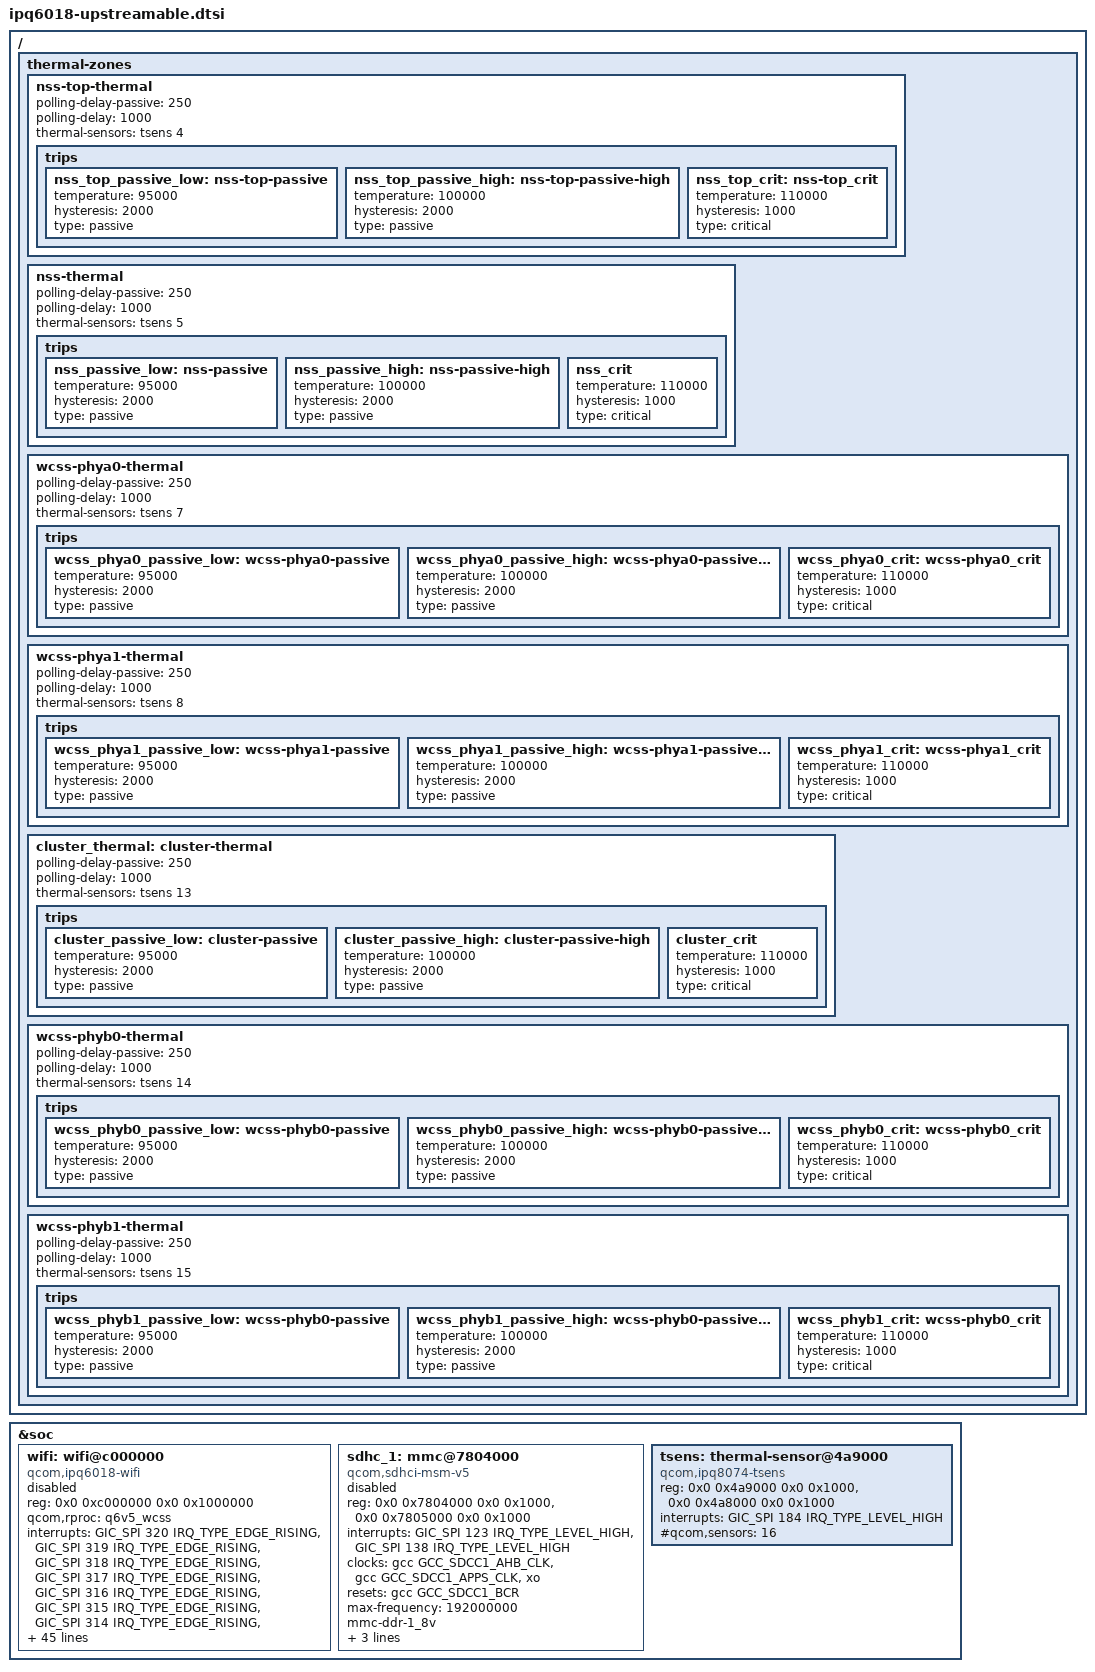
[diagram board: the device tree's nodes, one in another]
/*
 * Copyright (c) 2019-2020, The Linux Foundation. All rights reserved.
 *
 * Permission to use, copy, modify, and/or distribute this software for any
 * purpose with or without fee is hereby granted, provided that the above
 * copyright notice and this permission notice appear in all copies.
 *
 * THE SOFTWARE IS PROVIDED "AS IS" AND THE AUTHOR DISCLAIMS ALL WARRANTIES
 * WITH REGARD TO THIS SOFTWARE INCLUDING ALL IMPLIED WARRANTIES OF
 * MERCHANTABILITY AND FITNESS. IN NO EVENT SHALL THE AUTHOR BE LIABLE FOR
 * ANY SPECIAL, DIRECT, INDIRECT, OR CONSEQUENTIAL DAMAGES OR ANY DAMAGES
 * WHATSOEVER RESULTING FROM LOSS OF USE, DATA OR PROFITS, WHETHER IN AN
 * ACTION OF CONTRACT, NEGLIGENCE OR OTHER TORTIOUS ACTION, ARISING OUT OF
 * OR IN CONNECTION WITH THE USE OR PERFORMANCE OF THIS SOFTWARE.
 */

#include <dt-bindings/thermal/thermal.h>

/ {
	thermal-zones {
		nss-top-thermal {
			polling-delay-passive = <250>;
			polling-delay = <1000>;

			thermal-sensors = <&tsens 4>;

			trips {
				nss_top_passive_low: nss-top-passive {
					temperature = <95000>;
					hysteresis = <2000>;
					type = "passive";
				};

				nss_top_passive_high: nss-top-passive-high {
					temperature = <100000>;
					hysteresis = <2000>;
					type = "passive";
				};

				nss_top_crit: nss-top_crit {
					temperature = <110000>;
					hysteresis = <1000>;
					type = "critical";
				};
			};
		};

		nss-thermal {
			polling-delay-passive = <250>;
			polling-delay = <1000>;

			thermal-sensors = <&tsens 5>;

			trips {
				nss_passive_low: nss-passive {
					temperature = <95000>;
					hysteresis = <2000>;
					type = "passive";
				};

				nss_passive_high: nss-passive-high {
					temperature = <100000>;
					hysteresis = <2000>;
					type = "passive";
				};

				nss_crit: nss_crit {
					temperature = <110000>;
					hysteresis = <1000>;
					type = "critical";
				};
			};
		};

		wcss-phya0-thermal {
			polling-delay-passive = <250>;
			polling-delay = <1000>;

			thermal-sensors = <&tsens 7>;

			trips {
				wcss_phya0_passive_low: wcss-phya0-passive {
					temperature = <95000>;
					hysteresis = <2000>;
					type = "passive";
				};

				wcss_phya0_passive_high: wcss-phya0-passive-high {
					temperature = <100000>;
					hysteresis = <2000>;
					type = "passive";
				};

				wcss_phya0_crit: wcss-phya0_crit {
					temperature = <110000>;
					hysteresis = <1000>;
					type = "critical";
				};
			};
		};

		wcss-phya1-thermal {
			polling-delay-passive = <250>;
			polling-delay = <1000>;

			thermal-sensors = <&tsens 8>;

			trips {
				wcss_phya1_passive_low: wcss-phya1-passive {
					temperature = <95000>;
					hysteresis = <2000>;
					type = "passive";
				};

				wcss_phya1_passive_high: wcss-phya1-passive-high {
					temperature = <100000>;
					hysteresis = <2000>;
					type = "passive";
				};

				wcss_phya1_crit: wcss-phya1_crit {
					temperature = <110000>;
					hysteresis = <1000>;
					type = "critical";
				};
			};
		};

		cluster_thermal: cluster-thermal {
			polling-delay-passive = <250>;
			polling-delay = <1000>;

			thermal-sensors = <&tsens 13>;

			trips {
				cluster_passive_low: cluster-passive {
					temperature = <95000>;
					hysteresis = <2000>;
					type = "passive";
				};

				cluster_passive_high: cluster-passive-high {
					temperature = <100000>;
					hysteresis = <2000>;
					type = "passive";
				};

				cluster_crit: cluster_crit {
					temperature = <110000>;
					hysteresis = <1000>;
					type = "critical";
				};
			};
		};

		wcss-phyb0-thermal {
			polling-delay-passive = <250>;
			polling-delay = <1000>;

			thermal-sensors = <&tsens 14>;

			trips {
				wcss_phyb0_passive_low: wcss-phyb0-passive {
					temperature = <95000>;
					hysteresis = <2000>;
					type = "passive";
				};

				wcss_phyb0_passive_high: wcss-phyb0-passive-high {
					temperature = <100000>;
					hysteresis = <2000>;
					type = "passive";
				};

				wcss_phyb0_crit: wcss-phyb0_crit {
					temperature = <110000>;
					hysteresis = <1000>;
					type = "critical";
				};
			};
		};

		wcss-phyb1-thermal {
			polling-delay-passive = <250>;
			polling-delay = <1000>;

			thermal-sensors = <&tsens 15>;

			trips {
				wcss_phyb1_passive_low: wcss-phyb0-passive {
					temperature = <95000>;
					hysteresis = <2000>;
					type = "passive";
				};

				wcss_phyb1_passive_high: wcss-phyb0-passive-high {
					temperature = <100000>;
					hysteresis = <2000>;
					type = "passive";
				};

				wcss_phyb1_crit: wcss-phyb0_crit {
					temperature = <110000>;
					hysteresis = <1000>;
					type = "critical";
				};
			};
		};
	};

};

&soc {
	wifi: wifi@c000000 {
		compatible = "qcom,ipq6018-wifi";
		reg = <0x0 0xc000000 0x0 0x1000000>;
		qcom,rproc = <&q6v5_wcss>;
		interrupts = <GIC_SPI 320 IRQ_TYPE_EDGE_RISING>,
			     <GIC_SPI 319 IRQ_TYPE_EDGE_RISING>,
			     <GIC_SPI 318 IRQ_TYPE_EDGE_RISING>,
			     <GIC_SPI 317 IRQ_TYPE_EDGE_RISING>,
			     <GIC_SPI 316 IRQ_TYPE_EDGE_RISING>,
			     <GIC_SPI 315 IRQ_TYPE_EDGE_RISING>,
			     <GIC_SPI 314 IRQ_TYPE_EDGE_RISING>,
			     <GIC_SPI 311 IRQ_TYPE_EDGE_RISING>,
			     <GIC_SPI 310 IRQ_TYPE_EDGE_RISING>,
			     <GIC_SPI 411 IRQ_TYPE_EDGE_RISING>,
			     <GIC_SPI 410 IRQ_TYPE_EDGE_RISING>,
			     <GIC_SPI 40 IRQ_TYPE_EDGE_RISING>,
			     <GIC_SPI 39 IRQ_TYPE_EDGE_RISING>,
			     <GIC_SPI 302 IRQ_TYPE_EDGE_RISING>,
			     <GIC_SPI 301 IRQ_TYPE_EDGE_RISING>,
			     <GIC_SPI 37 IRQ_TYPE_EDGE_RISING>,
			     <GIC_SPI 36 IRQ_TYPE_EDGE_RISING>,
			     <GIC_SPI 296 IRQ_TYPE_EDGE_RISING>,
			     <GIC_SPI 295 IRQ_TYPE_EDGE_RISING>,
			     <GIC_SPI 294 IRQ_TYPE_EDGE_RISING>,
			     <GIC_SPI 293 IRQ_TYPE_EDGE_RISING>,
			     <GIC_SPI 292 IRQ_TYPE_EDGE_RISING>,
			     <GIC_SPI 291 IRQ_TYPE_EDGE_RISING>,
			     <GIC_SPI 290 IRQ_TYPE_EDGE_RISING>,
			     <GIC_SPI 289 IRQ_TYPE_EDGE_RISING>,
			     <GIC_SPI 288 IRQ_TYPE_EDGE_RISING>,
			     <GIC_SPI 239 IRQ_TYPE_EDGE_RISING>,
			     <GIC_SPI 236 IRQ_TYPE_EDGE_RISING>,
			     <GIC_SPI 235 IRQ_TYPE_EDGE_RISING>,
			     <GIC_SPI 234 IRQ_TYPE_EDGE_RISING>,
			     <GIC_SPI 233 IRQ_TYPE_EDGE_RISING>,
			     <GIC_SPI 232 IRQ_TYPE_EDGE_RISING>,
			     <GIC_SPI 231 IRQ_TYPE_EDGE_RISING>,
			     <GIC_SPI 230 IRQ_TYPE_EDGE_RISING>,
			     <GIC_SPI 229 IRQ_TYPE_EDGE_RISING>,
			     <GIC_SPI 228 IRQ_TYPE_EDGE_RISING>,
			     <GIC_SPI 224 IRQ_TYPE_EDGE_RISING>,
			     <GIC_SPI 223 IRQ_TYPE_EDGE_RISING>,
			     <GIC_SPI 203 IRQ_TYPE_EDGE_RISING>,
			     <GIC_SPI 183 IRQ_TYPE_EDGE_RISING>,
			     <GIC_SPI 180 IRQ_TYPE_EDGE_RISING>,
			     <GIC_SPI 179 IRQ_TYPE_EDGE_RISING>,
			     <GIC_SPI 178 IRQ_TYPE_EDGE_RISING>,
			     <GIC_SPI 177 IRQ_TYPE_EDGE_RISING>,
			     <GIC_SPI 176 IRQ_TYPE_EDGE_RISING>,
			     <GIC_SPI 163 IRQ_TYPE_EDGE_RISING>,
			     <GIC_SPI 162 IRQ_TYPE_EDGE_RISING>,
			     <GIC_SPI 160 IRQ_TYPE_EDGE_RISING>,
			     <GIC_SPI 159 IRQ_TYPE_EDGE_RISING>,
			     <GIC_SPI 158 IRQ_TYPE_EDGE_RISING>,
			     <GIC_SPI 157 IRQ_TYPE_EDGE_RISING>,
			     <GIC_SPI 156 IRQ_TYPE_EDGE_RISING>;
		interrupt-names = "misc-pulse1", "misc-latch", "sw-exception",
				  "watchdog", "ce0", "ce1", "ce2", "ce3", "ce4",
				  "ce5", "ce6", "ce7", "ce8", "ce9", "ce10",
				  "ce11", "host2wbm-desc-feed",
				  "host2reo-re-injection", "host2reo-command",
				  "host2rxdma-monitor-ring3",
				  "host2rxdma-monitor-ring2",
				  "host2rxdma-monitor-ring1",
				  "reo2ost-exception", "wbm2host-rx-release",
				  "reo2host-status",
				  "reo2host-destination-ring4",
				  "reo2host-destination-ring3",
				  "reo2host-destination-ring2",
				  "reo2host-destination-ring1",
				  "rxdma2host-monitor-destination-mac3",
				  "rxdma2host-monitor-destination-mac2",
				  "rxdma2host-monitor-destination-mac1",
				  "ppdu-end-interrupts-mac3",
				  "ppdu-end-interrupts-mac2",
				  "ppdu-end-interrupts-mac1",
				  "rxdma2host-monitor-status-ring-mac3",
				  "rxdma2host-monitor-status-ring-mac2",
				  "rxdma2host-monitor-status-ring-mac1",
				  "host2rxdma-host-buf-ring-mac3",
				  "host2rxdma-host-buf-ring-mac2",
				  "host2rxdma-host-buf-ring-mac1",
				  "rxdma2host-destination-ring-mac3",
				  "rxdma2host-destination-ring-mac2",
				  "rxdma2host-destination-ring-mac1",
				  "host2tcl-input-ring4",
				  "host2tcl-input-ring3",
				  "host2tcl-input-ring2",
				  "host2tcl-input-ring1",
				  "wbm2host-tx-completions-ring3",
				  "wbm2host-tx-completions-ring2",
				  "wbm2host-tx-completions-ring1",
				  "tcl2host-status-ring";
		status = "disabled";
	};

	sdhc_1: mmc@7804000 {
		compatible = "qcom,sdhci-msm-v5";
		reg = <0x0 0x7804000 0x0 0x1000>, <0x0 0x7805000 0x0 0x1000>;
		reg-names = "hc", "core";

		interrupts = <GIC_SPI 123 IRQ_TYPE_LEVEL_HIGH>,
					<GIC_SPI 138 IRQ_TYPE_LEVEL_HIGH>;
		interrupt-names = "hc_irq", "pwr_irq";

		clocks = <&gcc GCC_SDCC1_AHB_CLK>,
				<&gcc GCC_SDCC1_APPS_CLK>,
				<&xo>;
		clock-names = "iface", "core", "xo";
		resets = <&gcc GCC_SDCC1_BCR>;
		max-frequency = <192000000>;
		mmc-ddr-1_8v;
		mmc-hs200-1_8v;
		mmc-hs400-1_8v;
		bus-width = <8>;

		status = "disabled";
	};
	
	tsens: thermal-sensor@4a9000 {
			compatible = "qcom,ipq8074-tsens";
			reg = <0x0 0x4a9000 0x0 0x1000>, /* TM */
			      <0x0 0x4a8000 0x0 0x1000>; /* SROT */
			interrupts = <GIC_SPI 184 IRQ_TYPE_LEVEL_HIGH>;
			interrupt-names = "combined";
			#qcom,sensors = <16>;
			#thermal-sensor-cells = <1>;
	};
};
